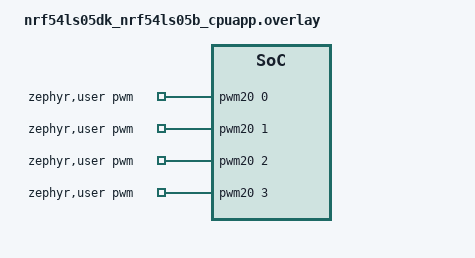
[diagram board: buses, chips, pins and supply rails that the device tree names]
/*
 * Copyright (c) 2025 Nordic Semiconductor ASA
 *
 * SPDX-License-Identifier: LicenseRef-Nordic-5-Clause
 */

/ {
	zephyr,user {
		pwms = <&pwm20 0 1600000 PWM_POLARITY_NORMAL>,
		       <&pwm20 1 1600000 PWM_POLARITY_NORMAL>,
		       <&pwm20 2 1600000 PWM_POLARITY_NORMAL>,
		       <&pwm20 3 1600000 PWM_POLARITY_NORMAL>;
	};
};
